# PADCFG_CTRL0_CFG0 register map
Vendor: Texas Instruments
Peripheral module from a debugger description file (folder am243x).
Registers are 32-bit, read-write, reset 0x214007 unless marked. A register's access mark holds for its fields unless they carry their own. Offsets are as the file gives them; lines under a group give offsets from that group; [hi:lo] are bit positions; {n}, {i} and the like mark numbered series; 'fields as' and 'values as' point back to an identical list; <NAME> marks a mode.

## PADCFG_CTRL0_CFG0
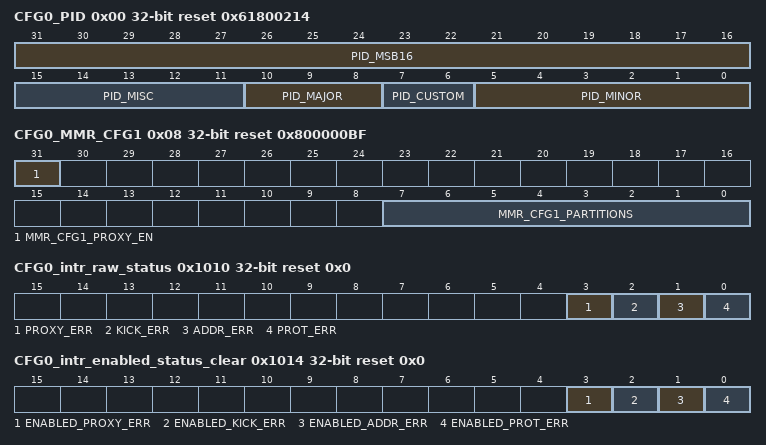
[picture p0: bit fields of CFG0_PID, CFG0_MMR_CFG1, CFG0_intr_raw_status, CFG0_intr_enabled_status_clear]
0x00 CFG0_PID ro reset 0x61800214
  [31:16] PID_MSB16, [15:11] PID_MISC, [10:8] PID_MAJOR, [7:6] PID_CUSTOM, [5:0] PID_MINOR
0x08 CFG0_MMR_CFG1 ro reset 0x800000BF
  [31] MMR_CFG1_PROXY_EN — Proxy addressing enabled
  [7:0] MMR_CFG1_PARTITIONS — Indicates present partitions
0x1008 CFG0_LOCK0_KICK0 reset 0x0
  [31:0] LOCK0_KICK0 — - KICK0 component
0x100C CFG0_LOCK0_KICK1 reset 0x0
  [31:0] LOCK0_KICK1 — - KICK1 component
0x1010 CFG0_intr_raw_status access not given reset 0x0
  [3] PROXY_ERR — Proxy0 access violation error. Raw status is read. Write a 1 to set the status. Writing a 0 has no effect. (access R/W1TS)
  [2] KICK_ERR — Kick access violation error. Raw status is read. Write a 1 to set the status. Writing a 0 has no effect. (access R/W1TS)
  [1] ADDR_ERR — Addressing violation error. Raw status is read. Write a 1 to set the status. Writing a 0 has no effect. (access R/W1TS)
  [0] PROT_ERR — Protection violation error. Raw status is read. Write a 1 to set the status. Writing a 0 has no effect. (access R/W1TS)
0x1014 CFG0_intr_enabled_status_clear access not given reset 0x0
  [3] ENABLED_PROXY_ERR — Proxy0 access violation error. Enabled status is read. Write a 1 to clear the status. Writing a 0 has no effect. (access R/W1TC)
  [2] ENABLED_KICK_ERR — Kick access violation error. Enabled status is read. Write a 1 to clear the status. Writing a 0 has no effect. (access R/W1TC)
  [1] ENABLED_ADDR_ERR — Addressing violation error. Enabled status is read. Write a 1 to clear the status. Writing a 0 has no effect. (access R/W1TC)
  [0] ENABLED_PROT_ERR — Protection violation error. Enabled status is read. Write a 1 to clear the status. Writing a 0 has no effect. (access R/W1TC)
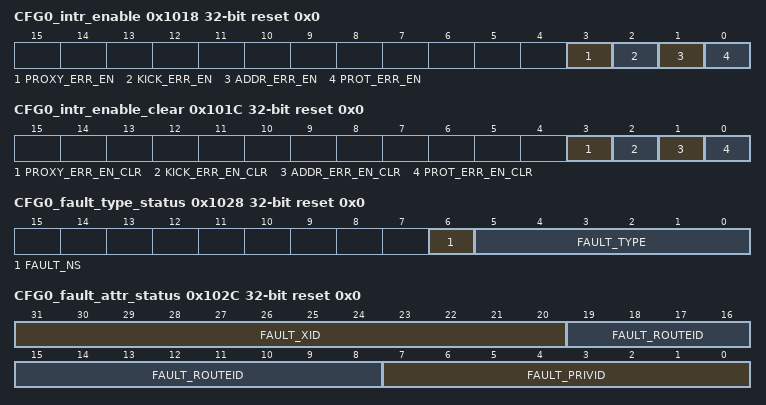
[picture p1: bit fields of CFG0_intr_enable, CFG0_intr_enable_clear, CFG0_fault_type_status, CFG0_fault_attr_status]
0x1018 CFG0_intr_enable access not given reset 0x0
  [3] PROXY_ERR_EN — Proxy0 access violation error enable. Write a 1 to set the enable. Writing a 0 has no effect. (access R/W1TS)
  [2] KICK_ERR_EN — Kick access violation error enable. Write a 1 to set the enable. Writing a 0 has no effect. (access R/W1TS)
  [1] ADDR_ERR_EN — Addressing violation error enable. Write a 1 to set the enable. Writing a 0 has no effect. (access R/W1TS)
  [0] PROT_ERR_EN — Protection violation error enable. Write a 1 to set the enable. Writing a 0 has no effect. (access R/W1TS)
0x101C CFG0_intr_enable_clear access not given reset 0x0
  [3] PROXY_ERR_EN_CLR — Proxy0 access violation error enable clear. Write a 1 to clear the enable. Writing a 0 has no effect. (access R/W1TC)
  [2] KICK_ERR_EN_CLR — Kick access violation error enable clear. Write a 1 to clear the enable. Writing a 0 has no effect. (access R/W1TC)
  [1] ADDR_ERR_EN_CLR — Addressing violation error enable clear. Write a 1 to clear the enable. Writing a 0 has no effect. (access R/W1TC)
  [0] PROT_ERR_EN_CLR — Protection violation error enable clear. Write a 1 to clear the enable. Writing a 0 has no effect. (access R/W1TC)
0x1020 CFG0_eoi reset 0x0
  [7:0] EOI_VECTOR — EOI vector value. Write this with interrupt distribution value in the chip.
0x1024 CFG0_fault_address ro reset 0x0
  [31:0] FAULT_ADDR — Fault Address.
0x1028 CFG0_fault_type_status ro reset 0x0
  [6] FAULT_NS — Non-secure access.
  [5:0] FAULT_TYPE — Fault Type 10_0000 = Supervisor read fault - priv = 1 dir = 1 dtype != 1 01_0000 = Supervisor write fault - priv = 1 dir = 0 00_1000 = Supervisor execute fault - priv = 1 dir = 1 dtype = 1 00_0100 = User read fault - priv = 0 dir = 1 dtype = 1 00_0010 = User write fault - priv = 0 dir = 0 00_0001 = User execute fault - priv = 0 dir = 1 dtype = 1 00_0000 = No fault
0x102C CFG0_fault_attr_status ro reset 0x0
  [31:20] FAULT_XID — XID.
  [19:8] FAULT_ROUTEID — Route ID.
  [7:0] FAULT_PRIVID — Privilege ID.
0x1030 CFG0_fault_clear wo reset 0x0
  [0] FAULT_CLR — Fault clear. Writing a 1 clears the current fault. Writing a 0 has no effect.
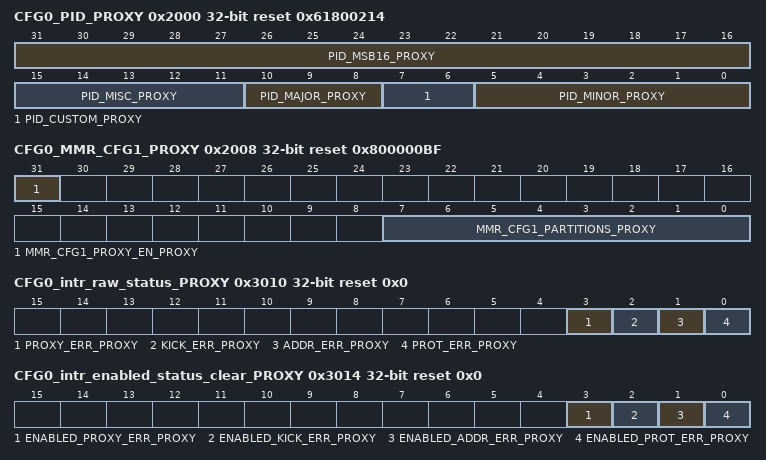
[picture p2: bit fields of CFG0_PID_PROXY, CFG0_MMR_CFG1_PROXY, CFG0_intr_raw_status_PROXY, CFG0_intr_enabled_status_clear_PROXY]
0x2000 CFG0_PID_PROXY ro reset 0x61800214
  [31:16] PID_MSB16_PROXY, [15:11] PID_MISC_PROXY, [10:8] PID_MAJOR_PROXY, [7:6] PID_CUSTOM_PROXY, [5:0] PID_MINOR_PROXY
0x2008 CFG0_MMR_CFG1_PROXY ro reset 0x800000BF
  [31] MMR_CFG1_PROXY_EN_PROXY — Proxy addressing enabled
  [7:0] MMR_CFG1_PARTITIONS_PROXY — Indicates present partitions
0x3008 CFG0_LOCK0_KICK0_PROXY reset 0x0
  [31:0] LOCK0_KICK0_PROXY — - KICK0 component
0x300C CFG0_LOCK0_KICK1_PROXY reset 0x0
  [31:0] LOCK0_KICK1_PROXY — - KICK1 component
0x3010 CFG0_intr_raw_status_PROXY access not given reset 0x0
  [3] PROXY_ERR_PROXY — Proxy0 access violation error. Raw status is read. Write a 1 to set the status. Writing a 0 has no effect. (access R/W1TS)
  [2] KICK_ERR_PROXY — Kick access violation error. Raw status is read. Write a 1 to set the status. Writing a 0 has no effect. (access R/W1TS)
  [1] ADDR_ERR_PROXY — Addressing violation error. Raw status is read. Write a 1 to set the status. Writing a 0 has no effect. (access R/W1TS)
  [0] PROT_ERR_PROXY — Protection violation error. Raw status is read. Write a 1 to set the status. Writing a 0 has no effect. (access R/W1TS)
0x3014 CFG0_intr_enabled_status_clear_PROXY access not given reset 0x0
  [3] ENABLED_PROXY_ERR_PROXY — Proxy0 access violation error. Enabled status is read. Write a 1 to clear the status. Writing a 0 has no effect. (access R/W1TC)
  [2] ENABLED_KICK_ERR_PROXY — Kick access violation error. Enabled status is read. Write a 1 to clear the status. Writing a 0 has no effect. (access R/W1TC)
  [1] ENABLED_ADDR_ERR_PROXY — Addressing violation error. Enabled status is read. Write a 1 to clear the status. Writing a 0 has no effect. (access R/W1TC)
  [0] ENABLED_PROT_ERR_PROXY — Protection violation error. Enabled status is read. Write a 1 to clear the status. Writing a 0 has no effect. (access R/W1TC)
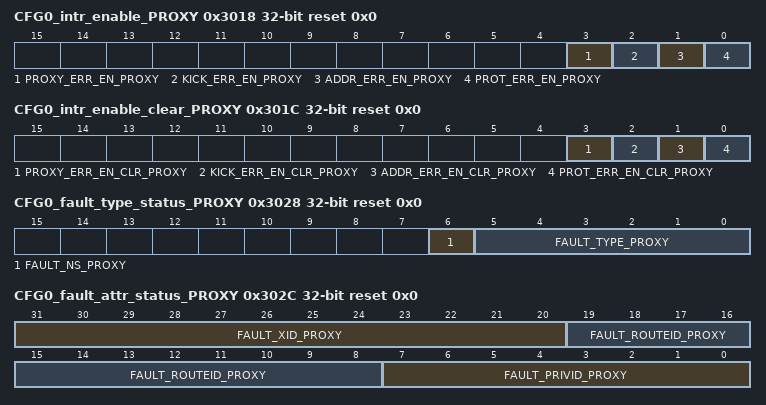
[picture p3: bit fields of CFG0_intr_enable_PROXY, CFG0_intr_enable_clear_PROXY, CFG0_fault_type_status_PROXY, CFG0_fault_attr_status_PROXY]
0x3018 CFG0_intr_enable_PROXY access not given reset 0x0
  [3] PROXY_ERR_EN_PROXY — Proxy0 access violation error enable. Write a 1 to set the enable. Writing a 0 has no effect. (access R/W1TS)
  [2] KICK_ERR_EN_PROXY — Kick access violation error enable. Write a 1 to set the enable. Writing a 0 has no effect. (access R/W1TS)
  [1] ADDR_ERR_EN_PROXY — Addressing violation error enable. Write a 1 to set the enable. Writing a 0 has no effect. (access R/W1TS)
  [0] PROT_ERR_EN_PROXY — Protection violation error enable. Write a 1 to set the enable. Writing a 0 has no effect. (access R/W1TS)
0x301C CFG0_intr_enable_clear_PROXY access not given reset 0x0
  [3] PROXY_ERR_EN_CLR_PROXY — Proxy0 access violation error enable clear. Write a 1 to clear the enable. Writing a 0 has no effect. (access R/W1TC)
  [2] KICK_ERR_EN_CLR_PROXY — Kick access violation error enable clear. Write a 1 to clear the enable. Writing a 0 has no effect. (access R/W1TC)
  [1] ADDR_ERR_EN_CLR_PROXY — Addressing violation error enable clear. Write a 1 to clear the enable. Writing a 0 has no effect. (access R/W1TC)
  [0] PROT_ERR_EN_CLR_PROXY — Protection violation error enable clear. Write a 1 to clear the enable. Writing a 0 has no effect. (access R/W1TC)
0x3020 CFG0_eoi_PROXY reset 0x0
  [7:0] EOI_VECTOR_PROXY — EOI vector value. Write this with interrupt distribution value in the chip.
0x3024 CFG0_fault_address_PROXY ro reset 0x0
  [31:0] FAULT_ADDR_PROXY — Fault Address.
0x3028 CFG0_fault_type_status_PROXY ro reset 0x0
  [6] FAULT_NS_PROXY — Non-secure access.
  [5:0] FAULT_TYPE_PROXY — Fault Type 10_0000 = Supervisor read fault - priv = 1 dir = 1 dtype != 1 01_0000 = Supervisor write fault - priv = 1 dir = 0 00_1000 = Supervisor execute fault - priv = 1 dir = 1 dtype = 1 00_0100 = User read fault - priv = 0 dir = 1 dtype = 1 00_0010 = User write fault - priv = 0 dir = 0 00_0001 = User execute fault - priv = 0 dir = 1 dtype = 1 00_0000 = No fault
0x302C CFG0_fault_attr_status_PROXY ro reset 0x0
  [31:20] FAULT_XID_PROXY — XID.
  [19:8] FAULT_ROUTEID_PROXY — Route ID.
  [7:0] FAULT_PRIVID_PROXY — Privilege ID.
0x3030 CFG0_fault_clear_PROXY wo reset 0x0
  [0] FAULT_CLR_PROXY — Fault clear. Writing a 1 clears the current fault. Writing a 0 has no effect.
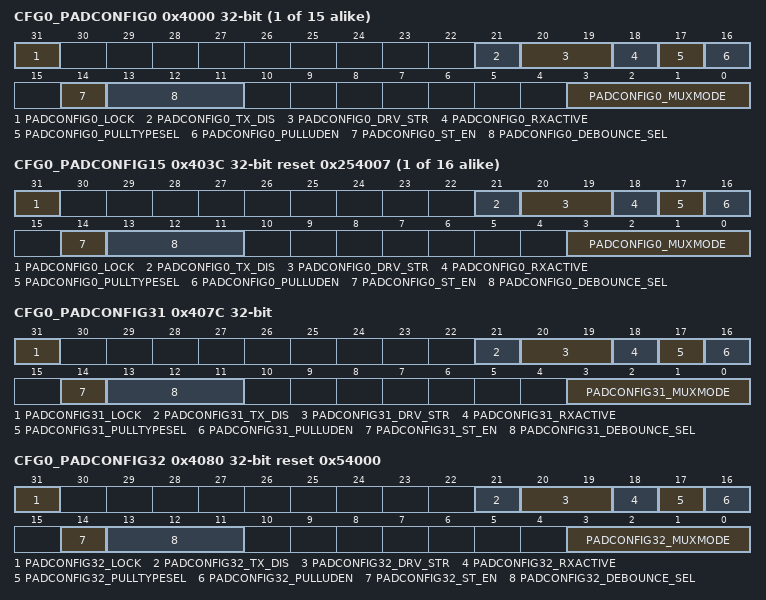
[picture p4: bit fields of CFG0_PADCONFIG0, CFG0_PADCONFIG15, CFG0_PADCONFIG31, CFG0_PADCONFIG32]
{0x4000+4i} CFG0_PADCONFIG{i} (i=0..14)
  [31] PADCONFIG{i}_LOCK — Lock 0 - Padconfig register is unlocked 1 - Padconfig register is locked from further writes
  [21] PADCONFIG{i}_TX_DIS — Driver Disable 0 - Driver is enabled 1 - Driver is disabled
  [20:19] PADCONFIG{i}_DRV_STR — Drive Strength Control . Selects the drive strength value for LVCMOS pins. (Does not apply to other pin types)
  [18] PADCONFIG{i}_RXACTIVE — Input enable for the Pad 0 - Receiver disabled 1 - Receiver enabled
  [17] PADCONFIG{i}_PULLTYPESEL — Pad Pullup / Pulldown type selection 0 - Pulldown selected 1 - Pullup selected
  [16] PADCONFIG{i}_PULLUDEN — Pad Pullup / Pulldown enable. This is an active low signal. 0 - Pullup / Pulldown enabled 1 - Pullup / Pulldown disabled
  [14] PADCONFIG{i}_ST_EN — Receiver Schmitt Trigger enable 0 - Schmitt trigger input disabled 1 - Schmitt trigger input enabled
  [13:11] PADCONFIG{i}_DEBOUNCE_SEL — Selects the debouce period for the pad.
  [3:0] PADCONFIG{i}_MUXMODE — Pad functional signal mux selection Field values (others are reserved): 4'b0000 - Mux Mode 0 4'b0001 - Mux Mode 1 4'b0010 - Mux Mode 2 4'b0011 - Mux Mode 3 4'b0100 - Mux Mode 4 4'b0101 - Mux Mode 5 4'b0110 - Mux Mode 6 4'b0111 - Mux Mode 7 4'b1000 - Mux Mode 8 4'b1001 - Mux Mode 9 4'b1010 - Mux Mode 10 4'b1011 - Mux Mode 11 4'b1100 - Mux Mode 12 4'b1101 - Mux Mode 13 4'b1110 - Mux Mode 14 4'b1111 - Mux Mode 15
{0x4000+4i} CFG0_PADCONFIG{i} reset 0x254007 (i=15..30)
  fields as CFG0_PADCONFIG0
0x407C CFG0_PADCONFIG31
  [31] PADCONFIG31_LOCK — Lock 0 - Padconfig register is unlocked 1 - Padconfig register is locked from further writes
  [21] PADCONFIG31_TX_DIS — Driver Disable 0 - Driver is enabled 1 - Driver is disabled
  [20:19] PADCONFIG31_DRV_STR — Drive Strength Control . Selects the drive strength value for LVCMOS pins. (Does not apply to other pin types)
  [18] PADCONFIG31_RXACTIVE — Input enable for the Pad 0 - Receiver disabled 1 - Receiver enabled
  [17] PADCONFIG31_PULLTYPESEL — Pad Pullup / Pulldown type selection 0 - Pulldown selected 1 - Pullup selected
  [16] PADCONFIG31_PULLUDEN — Pad Pullup / Pulldown enable. This is an active low signal. 0 - Pullup / Pulldown enabled 1 - Pullup / Pulldown disabled
  [14] PADCONFIG31_ST_EN — Receiver Schmitt Trigger enable 0 - Schmitt trigger input disabled 1 - Schmitt trigger input enabled
  [13:11] PADCONFIG31_DEBOUNCE_SEL — Selects the debouce period for the pad.
  [3:0] PADCONFIG31_MUXMODE — Pad functional signal mux selection Field values (others are reserved): 4'b0000 - Mux Mode 0 4'b0001 - Mux Mode 1 4'b0010 - Mux Mode 2 4'b0011 - Mux Mode 3 4'b0100 - Mux Mode 4 4'b0101 - Mux Mode 5 4'b0110 - Mux Mode 6 4'b0111 - Mux Mode 7 4'b1000 - Mux Mode 8 4'b1001 - Mux Mode 9 4'b1010 - Mux Mode 10 4'b1011 - Mux Mode 11 4'b1100 - Mux Mode 12 4'b1101 - Mux Mode 13 4'b1110 - Mux Mode 14 4'b1111 - Mux Mode 15
0x4080 CFG0_PADCONFIG32 reset 0x54000
  [31] PADCONFIG32_LOCK — Lock 0 - Padconfig register is unlocked 1 - Padconfig register is locked from further writes
  [21] PADCONFIG32_TX_DIS — Driver Disable 0 - Driver is enabled 1 - Driver is disabled
  [20:19] PADCONFIG32_DRV_STR — Drive Strength Control . Selects the drive strength value for LVCMOS pins. (Does not apply to other pin types)
  [18] PADCONFIG32_RXACTIVE — Input enable for the Pad 0 - Receiver disabled 1 - Receiver enabled
  [17] PADCONFIG32_PULLTYPESEL — Pad Pullup / Pulldown type selection 0 - Pulldown selected 1 - Pullup selected
  [16] PADCONFIG32_PULLUDEN — Pad Pullup / Pulldown enable. This is an active low signal. 0 - Pullup / Pulldown enabled 1 - Pullup / Pulldown disabled
  [14] PADCONFIG32_ST_EN — Receiver Schmitt Trigger enable 0 - Schmitt trigger input disabled 1 - Schmitt trigger input enabled
  [13:11] PADCONFIG32_DEBOUNCE_SEL — Selects the debouce period for the pad.
  [3:0] PADCONFIG32_MUXMODE — Pad functional signal mux selection Field values (others are reserved): 4'b0000 - Mux Mode 0 4'b0001 - Mux Mode 1 4'b0010 - Mux Mode 2 4'b0011 - Mux Mode 3 4'b0100 - Mux Mode 4 4'b0101 - Mux Mode 5 4'b0110 - Mux Mode 6 4'b0111 - Mux Mode 7 4'b1000 - Mux Mode 8 4'b1001 - Mux Mode 9 4'b1010 - Mux Mode 10 4'b1011 - Mux Mode 11 4'b1100 - Mux Mode 12 4'b1101 - Mux Mode 13 4'b1110 - Mux Mode 14 4'b1111 - Mux Mode 15
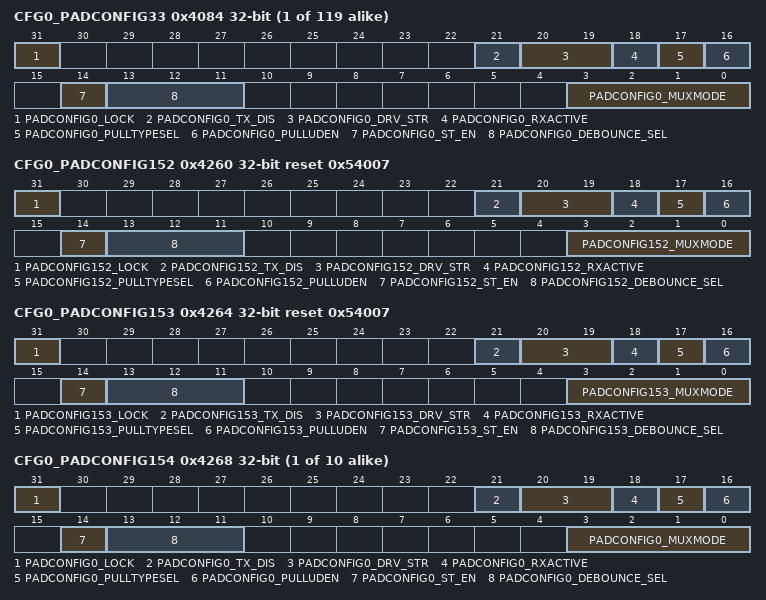
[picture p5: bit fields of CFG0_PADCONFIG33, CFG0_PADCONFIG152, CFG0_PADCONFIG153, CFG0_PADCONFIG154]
{0x4000+4i} CFG0_PADCONFIG{i} (i=33..151)
  fields as CFG0_PADCONFIG0
0x4260 CFG0_PADCONFIG152 reset 0x54007
  [31] PADCONFIG152_LOCK — Lock 0 - Padconfig register is unlocked 1 - Padconfig register is locked from further writes
  [21] PADCONFIG152_TX_DIS — Driver Disable 0 - Driver is enabled 1 - Driver is disabled
  [20:19] PADCONFIG152_DRV_STR — Drive Strength Control . Selects the drive strength value for LVCMOS pins. (Does not apply to other pin types)
  [18] PADCONFIG152_RXACTIVE — Input enable for the Pad 0 - Receiver disabled 1 - Receiver enabled
  [17] PADCONFIG152_PULLTYPESEL — Pad Pullup / Pulldown type selection 0 - Pulldown selected 1 - Pullup selected
  [16] PADCONFIG152_PULLUDEN — Pad Pullup / Pulldown enable. This is an active low signal. 0 - Pullup / Pulldown enabled 1 - Pullup / Pulldown disabled
  [14] PADCONFIG152_ST_EN — Receiver Schmitt Trigger enable 0 - Schmitt trigger input disabled 1 - Schmitt trigger input enabled
  [13:11] PADCONFIG152_DEBOUNCE_SEL — Selects the debouce period for the pad.
  [3:0] PADCONFIG152_MUXMODE — Pad functional signal mux selection Field values (others are reserved): 4'b0000 - Mux Mode 0 4'b0001 - Mux Mode 1 4'b0010 - Mux Mode 2 4'b0011 - Mux Mode 3 4'b0100 - Mux Mode 4 4'b0101 - Mux Mode 5 4'b0110 - Mux Mode 6 4'b0111 - Mux Mode 7 4'b1000 - Mux Mode 8 4'b1001 - Mux Mode 9 4'b1010 - Mux Mode 10 4'b1011 - Mux Mode 11 4'b1100 - Mux Mode 12 4'b1101 - Mux Mode 13 4'b1110 - Mux Mode 14 4'b1111 - Mux Mode 15
0x4264 CFG0_PADCONFIG153 reset 0x54007
  [31] PADCONFIG153_LOCK — Lock 0 - Padconfig register is unlocked 1 - Padconfig register is locked from further writes
  [21] PADCONFIG153_TX_DIS — Driver Disable 0 - Driver is enabled 1 - Driver is disabled
  [20:19] PADCONFIG153_DRV_STR — Drive Strength Control . Selects the drive strength value for LVCMOS pins. (Does not apply to other pin types)
  [18] PADCONFIG153_RXACTIVE — Input enable for the Pad 0 - Receiver disabled 1 - Receiver enabled
  [17] PADCONFIG153_PULLTYPESEL — Pad Pullup / Pulldown type selection 0 - Pulldown selected 1 - Pullup selected
  [16] PADCONFIG153_PULLUDEN — Pad Pullup / Pulldown enable. This is an active low signal. 0 - Pullup / Pulldown enabled 1 - Pullup / Pulldown disabled
  [14] PADCONFIG153_ST_EN — Receiver Schmitt Trigger enable 0 - Schmitt trigger input disabled 1 - Schmitt trigger input enabled
  [13:11] PADCONFIG153_DEBOUNCE_SEL — Selects the debouce period for the pad.
  [3:0] PADCONFIG153_MUXMODE — Pad functional signal mux selection Field values (others are reserved): 4'b0000 - Mux Mode 0 4'b0001 - Mux Mode 1 4'b0010 - Mux Mode 2 4'b0011 - Mux Mode 3 4'b0100 - Mux Mode 4 4'b0101 - Mux Mode 5 4'b0110 - Mux Mode 6 4'b0111 - Mux Mode 7 4'b1000 - Mux Mode 8 4'b1001 - Mux Mode 9 4'b1010 - Mux Mode 10 4'b1011 - Mux Mode 11 4'b1100 - Mux Mode 12 4'b1101 - Mux Mode 13 4'b1110 - Mux Mode 14 4'b1111 - Mux Mode 15
{0x4000+4i} CFG0_PADCONFIG{i} (i=154..163)
  fields as CFG0_PADCONFIG0
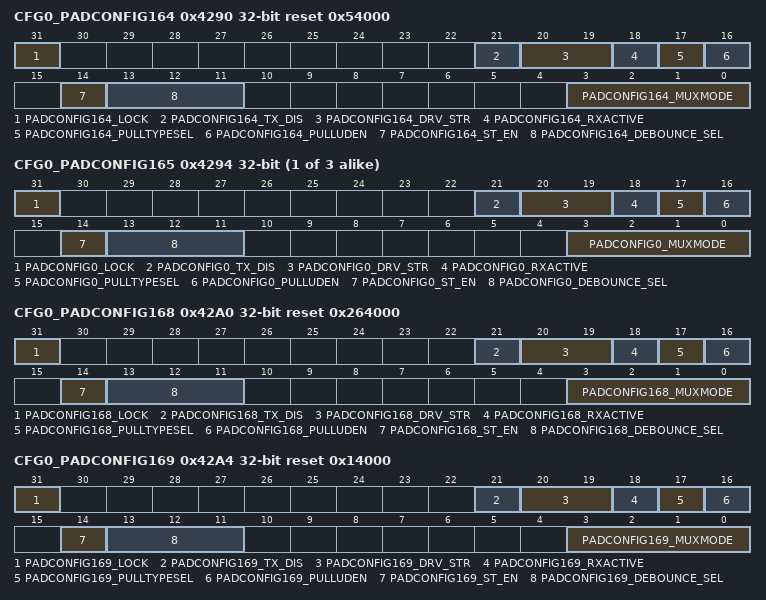
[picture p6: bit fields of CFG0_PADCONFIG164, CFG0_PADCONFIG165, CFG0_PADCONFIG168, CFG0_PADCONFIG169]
0x4290 CFG0_PADCONFIG164 reset 0x54000
  [31] PADCONFIG164_LOCK — Lock 0 - Padconfig register is unlocked 1 - Padconfig register is locked from further writes
  [21] PADCONFIG164_TX_DIS — Driver Disable 0 - Driver is enabled 1 - Driver is disabled
  [20:19] PADCONFIG164_DRV_STR — Drive Strength Control . Selects the drive strength value for LVCMOS pins. (Does not apply to other pin types)
  [18] PADCONFIG164_RXACTIVE — Input enable for the Pad 0 - Receiver disabled 1 - Receiver enabled
  [17] PADCONFIG164_PULLTYPESEL — Pad Pullup / Pulldown type selection 0 - Pulldown selected 1 - Pullup selected
  [16] PADCONFIG164_PULLUDEN — Pad Pullup / Pulldown enable. This is an active low signal. 0 - Pullup / Pulldown enabled 1 - Pullup / Pulldown disabled
  [14] PADCONFIG164_ST_EN — Receiver Schmitt Trigger enable 0 - Schmitt trigger input disabled 1 - Schmitt trigger input enabled
  [13:11] PADCONFIG164_DEBOUNCE_SEL — Selects the debouce period for the pad.
  [3:0] PADCONFIG164_MUXMODE — Pad functional signal mux selection Field values (others are reserved): 4'b0000 - Mux Mode 0 4'b0001 - Mux Mode 1 4'b0010 - Mux Mode 2 4'b0011 - Mux Mode 3 4'b0100 - Mux Mode 4 4'b0101 - Mux Mode 5 4'b0110 - Mux Mode 6 4'b0111 - Mux Mode 7 4'b1000 - Mux Mode 8 4'b1001 - Mux Mode 9 4'b1010 - Mux Mode 10 4'b1011 - Mux Mode 11 4'b1100 - Mux Mode 12 4'b1101 - Mux Mode 13 4'b1110 - Mux Mode 14 4'b1111 - Mux Mode 15
{0x4000+4i} CFG0_PADCONFIG{i} (i=165..167)
  fields as CFG0_PADCONFIG0
0x42A0 CFG0_PADCONFIG168 reset 0x264000
  [31] PADCONFIG168_LOCK — Lock 0 - Padconfig register is unlocked 1 - Padconfig register is locked from further writes
  [21] PADCONFIG168_TX_DIS — Driver Disable 0 - Driver is enabled 1 - Driver is disabled
  [20:19] PADCONFIG168_DRV_STR — Drive Strength Control . Selects the drive strength value for LVCMOS pins. (Does not apply to other pin types)
  [18] PADCONFIG168_RXACTIVE — Input enable for the Pad 0 - Receiver disabled 1 - Receiver enabled
  [17] PADCONFIG168_PULLTYPESEL — Pad Pullup / Pulldown type selection 0 - Pulldown selected 1 - Pullup selected
  [16] PADCONFIG168_PULLUDEN — Pad Pullup / Pulldown enable. This is an active low signal. 0 - Pullup / Pulldown enabled 1 - Pullup / Pulldown disabled
  [14] PADCONFIG168_ST_EN — Receiver Schmitt Trigger enable 0 - Schmitt trigger input disabled 1 - Schmitt trigger input enabled
  [13:11] PADCONFIG168_DEBOUNCE_SEL — Selects the debouce period for the pad.
  [3:0] PADCONFIG168_MUXMODE — Pad functional signal mux selection Field values (others are reserved): 4'b0000 - Mux Mode 0 4'b0001 - Mux Mode 1 4'b0010 - Mux Mode 2 4'b0011 - Mux Mode 3 4'b0100 - Mux Mode 4 4'b0101 - Mux Mode 5 4'b0110 - Mux Mode 6 4'b0111 - Mux Mode 7 4'b1000 - Mux Mode 8 4'b1001 - Mux Mode 9 4'b1010 - Mux Mode 10 4'b1011 - Mux Mode 11 4'b1100 - Mux Mode 12 4'b1101 - Mux Mode 13 4'b1110 - Mux Mode 14 4'b1111 - Mux Mode 15
0x42A4 CFG0_PADCONFIG169 reset 0x14000
  [31] PADCONFIG169_LOCK — Lock 0 - Padconfig register is unlocked 1 - Padconfig register is locked from further writes
  [21] PADCONFIG169_TX_DIS — Driver Disable 0 - Driver is enabled 1 - Driver is disabled
  [20:19] PADCONFIG169_DRV_STR — Drive Strength Control . Selects the drive strength value for LVCMOS pins. (Does not apply to other pin types)
  [18] PADCONFIG169_RXACTIVE — Input enable for the Pad 0 - Receiver disabled 1 - Receiver enabled
  [17] PADCONFIG169_PULLTYPESEL — Pad Pullup / Pulldown type selection 0 - Pulldown selected 1 - Pullup selected
  [16] PADCONFIG169_PULLUDEN — Pad Pullup / Pulldown enable. This is an active low signal. 0 - Pullup / Pulldown enabled 1 - Pullup / Pulldown disabled
  [14] PADCONFIG169_ST_EN — Receiver Schmitt Trigger enable 0 - Schmitt trigger input disabled 1 - Schmitt trigger input enabled
  [13:11] PADCONFIG169_DEBOUNCE_SEL — Selects the debouce period for the pad.
  [3:0] PADCONFIG169_MUXMODE — Pad functional signal mux selection Field values (others are reserved): 4'b0000 - Mux Mode 0 4'b0001 - Mux Mode 1 4'b0010 - Mux Mode 2 4'b0011 - Mux Mode 3 4'b0100 - Mux Mode 4 4'b0101 - Mux Mode 5 4'b0110 - Mux Mode 6 4'b0111 - Mux Mode 7 4'b1000 - Mux Mode 8 4'b1001 - Mux Mode 9 4'b1010 - Mux Mode 10 4'b1011 - Mux Mode 11 4'b1100 - Mux Mode 12 4'b1101 - Mux Mode 13 4'b1110 - Mux Mode 14 4'b1111 - Mux Mode 15
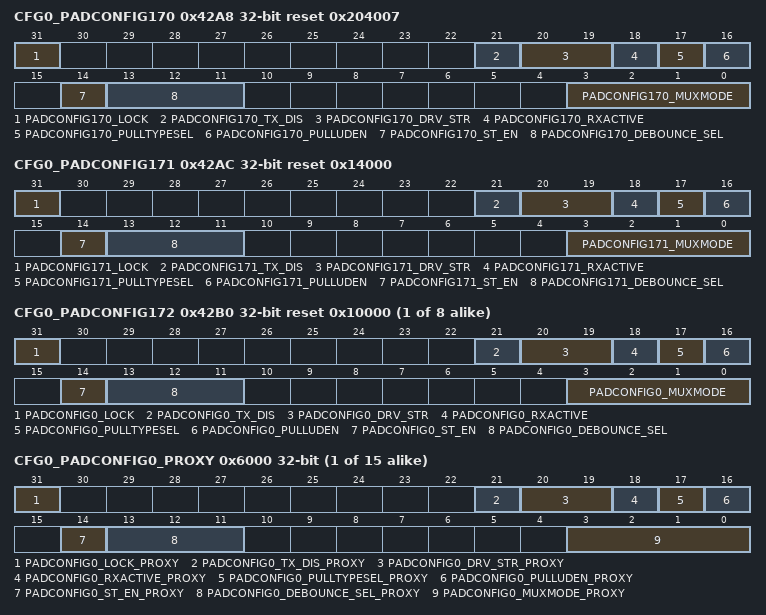
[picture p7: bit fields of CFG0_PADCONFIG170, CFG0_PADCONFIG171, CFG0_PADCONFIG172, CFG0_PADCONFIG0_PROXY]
0x42A8 CFG0_PADCONFIG170 reset 0x204007
  [31] PADCONFIG170_LOCK — Lock 0 - Padconfig register is unlocked 1 - Padconfig register is locked from further writes
  [21] PADCONFIG170_TX_DIS — Driver Disable 0 - Driver is enabled 1 - Driver is disabled
  [20:19] PADCONFIG170_DRV_STR — Drive Strength Control . Selects the drive strength value for LVCMOS pins. (Does not apply to other pin types)
  [18] PADCONFIG170_RXACTIVE — Input enable for the Pad 0 - Receiver disabled 1 - Receiver enabled
  [17] PADCONFIG170_PULLTYPESEL — Pad Pullup / Pulldown type selection 0 - Pulldown selected 1 - Pullup selected
  [16] PADCONFIG170_PULLUDEN — Pad Pullup / Pulldown enable. This is an active low signal. 0 - Pullup / Pulldown enabled 1 - Pullup / Pulldown disabled
  [14] PADCONFIG170_ST_EN — Receiver Schmitt Trigger enable 0 - Schmitt trigger input disabled 1 - Schmitt trigger input enabled
  [13:11] PADCONFIG170_DEBOUNCE_SEL — Selects the debouce period for the pad.
  [3:0] PADCONFIG170_MUXMODE — Pad functional signal mux selection Field values (others are reserved): 4'b0000 - Mux Mode 0 4'b0001 - Mux Mode 1 4'b0010 - Mux Mode 2 4'b0011 - Mux Mode 3 4'b0100 - Mux Mode 4 4'b0101 - Mux Mode 5 4'b0110 - Mux Mode 6 4'b0111 - Mux Mode 7 4'b1000 - Mux Mode 8 4'b1001 - Mux Mode 9 4'b1010 - Mux Mode 10 4'b1011 - Mux Mode 11 4'b1100 - Mux Mode 12 4'b1101 - Mux Mode 13 4'b1110 - Mux Mode 14 4'b1111 - Mux Mode 15
0x42AC CFG0_PADCONFIG171 reset 0x14000
  [31] PADCONFIG171_LOCK — Lock 0 - Padconfig register is unlocked 1 - Padconfig register is locked from further writes
  [21] PADCONFIG171_TX_DIS — Driver Disable 0 - Driver is enabled 1 - Driver is disabled
  [20:19] PADCONFIG171_DRV_STR — Drive Strength Control . Selects the drive strength value for LVCMOS pins. (Does not apply to other pin types)
  [18] PADCONFIG171_RXACTIVE — Input enable for the Pad 0 - Receiver disabled 1 - Receiver enabled
  [17] PADCONFIG171_PULLTYPESEL — Pad Pullup / Pulldown type selection 0 - Pulldown selected 1 - Pullup selected
  [16] PADCONFIG171_PULLUDEN — Pad Pullup / Pulldown enable. This is an active low signal. 0 - Pullup / Pulldown enabled 1 - Pullup / Pulldown disabled
  [14] PADCONFIG171_ST_EN — Receiver Schmitt Trigger enable 0 - Schmitt trigger input disabled 1 - Schmitt trigger input enabled
  [13:11] PADCONFIG171_DEBOUNCE_SEL — Selects the debouce period for the pad.
  [3:0] PADCONFIG171_MUXMODE — Pad functional signal mux selection Field values (others are reserved): 4'b0000 - Mux Mode 0 4'b0001 - Mux Mode 1 4'b0010 - Mux Mode 2 4'b0011 - Mux Mode 3 4'b0100 - Mux Mode 4 4'b0101 - Mux Mode 5 4'b0110 - Mux Mode 6 4'b0111 - Mux Mode 7 4'b1000 - Mux Mode 8 4'b1001 - Mux Mode 9 4'b1010 - Mux Mode 10 4'b1011 - Mux Mode 11 4'b1100 - Mux Mode 12 4'b1101 - Mux Mode 13 4'b1110 - Mux Mode 14 4'b1111 - Mux Mode 15
{0x4000+4i} CFG0_PADCONFIG{i} reset 0x10000 (i=172..179)
  fields as CFG0_PADCONFIG0
0x5008 CFG0_LOCK1_KICK0 reset 0x0
  [31:0] LOCK1_KICK0 — - KICK0 component
0x500C CFG0_LOCK1_KICK1 reset 0x0
  [31:0] LOCK1_KICK1 — - KICK1 component
{0x6000+4i} CFG0_PADCONFIG{i}_PROXY (i=0..14)
  [31] PADCONFIG{i}_LOCK_PROXY — Lock 0 - Padconfig register is unlocked 1 - Padconfig register is locked from further writes
  [21] PADCONFIG{i}_TX_DIS_PROXY — Driver Disable 0 - Driver is enabled 1 - Driver is disabled
  [20:19] PADCONFIG{i}_DRV_STR_PROXY — Drive Strength Control . Selects the drive strength value for LVCMOS pins. (Does not apply to other pin types)
  [18] PADCONFIG{i}_RXACTIVE_PROXY — Input enable for the Pad 0 - Receiver disabled 1 - Receiver enabled
  [17] PADCONFIG{i}_PULLTYPESEL_PROXY — Pad Pullup / Pulldown type selection 0 - Pulldown selected 1 - Pullup selected
  [16] PADCONFIG{i}_PULLUDEN_PROXY — Pad Pullup / Pulldown enable. This is an active low signal. 0 - Pullup / Pulldown enabled 1 - Pullup / Pulldown disabled
  [14] PADCONFIG{i}_ST_EN_PROXY — Receiver Schmitt Trigger enable 0 - Schmitt trigger input disabled 1 - Schmitt trigger input enabled
  [13:11] PADCONFIG{i}_DEBOUNCE_SEL_PROXY — Selects the debouce period for the pad.
  [3:0] PADCONFIG{i}_MUXMODE_PROXY — Pad functional signal mux selection Field values (others are reserved): 4'b0000 - Mux Mode 0 4'b0001 - Mux Mode 1 4'b0010 - Mux Mode 2 4'b0011 - Mux Mode 3 4'b0100 - Mux Mode 4 4'b0101 - Mux Mode 5 4'b0110 - Mux Mode 6 4'b0111 - Mux Mode 7 4'b1000 - Mux Mode 8 4'b1001 - Mux Mode 9 4'b1010 - Mux Mode 10 4'b1011 - Mux Mode 11 4'b1100 - Mux Mode 12 4'b1101 - Mux Mode 13 4'b1110 - Mux Mode 14 4'b1111 - Mux Mode 15
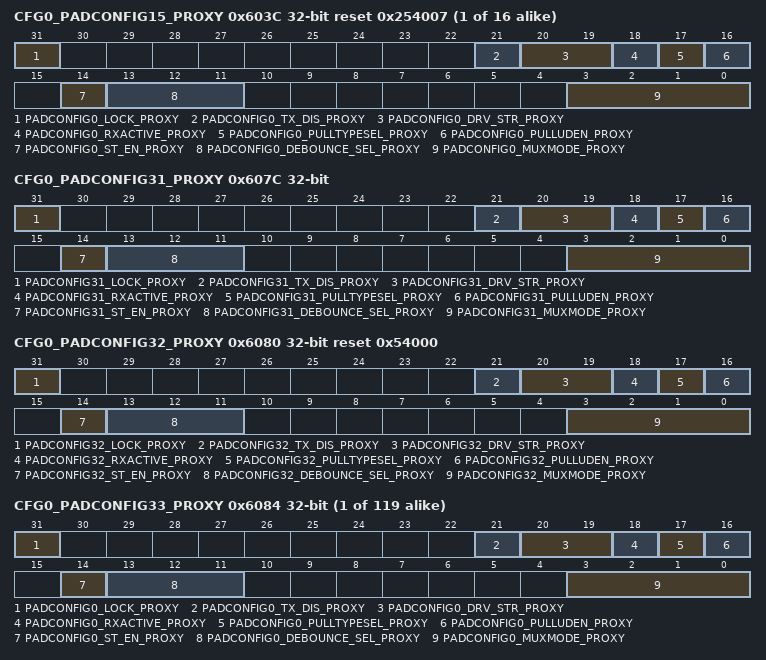
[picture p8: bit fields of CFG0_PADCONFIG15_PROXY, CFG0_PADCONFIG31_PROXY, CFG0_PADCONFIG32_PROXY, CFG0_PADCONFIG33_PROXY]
{0x6000+4i} CFG0_PADCONFIG{i}_PROXY reset 0x254007 (i=15..30)
  fields as CFG0_PADCONFIG0_PROXY
0x607C CFG0_PADCONFIG31_PROXY
  [31] PADCONFIG31_LOCK_PROXY — Lock 0 - Padconfig register is unlocked 1 - Padconfig register is locked from further writes
  [21] PADCONFIG31_TX_DIS_PROXY — Driver Disable 0 - Driver is enabled 1 - Driver is disabled
  [20:19] PADCONFIG31_DRV_STR_PROXY — Drive Strength Control . Selects the drive strength value for LVCMOS pins. (Does not apply to other pin types)
  [18] PADCONFIG31_RXACTIVE_PROXY — Input enable for the Pad 0 - Receiver disabled 1 - Receiver enabled
  [17] PADCONFIG31_PULLTYPESEL_PROXY — Pad Pullup / Pulldown type selection 0 - Pulldown selected 1 - Pullup selected
  [16] PADCONFIG31_PULLUDEN_PROXY — Pad Pullup / Pulldown enable. This is an active low signal. 0 - Pullup / Pulldown enabled 1 - Pullup / Pulldown disabled
  [14] PADCONFIG31_ST_EN_PROXY — Receiver Schmitt Trigger enable 0 - Schmitt trigger input disabled 1 - Schmitt trigger input enabled
  [13:11] PADCONFIG31_DEBOUNCE_SEL_PROXY — Selects the debouce period for the pad.
  [3:0] PADCONFIG31_MUXMODE_PROXY — Pad functional signal mux selection Field values (others are reserved): 4'b0000 - Mux Mode 0 4'b0001 - Mux Mode 1 4'b0010 - Mux Mode 2 4'b0011 - Mux Mode 3 4'b0100 - Mux Mode 4 4'b0101 - Mux Mode 5 4'b0110 - Mux Mode 6 4'b0111 - Mux Mode 7 4'b1000 - Mux Mode 8 4'b1001 - Mux Mode 9 4'b1010 - Mux Mode 10 4'b1011 - Mux Mode 11 4'b1100 - Mux Mode 12 4'b1101 - Mux Mode 13 4'b1110 - Mux Mode 14 4'b1111 - Mux Mode 15
0x6080 CFG0_PADCONFIG32_PROXY reset 0x54000
  [31] PADCONFIG32_LOCK_PROXY — Lock 0 - Padconfig register is unlocked 1 - Padconfig register is locked from further writes
  [21] PADCONFIG32_TX_DIS_PROXY — Driver Disable 0 - Driver is enabled 1 - Driver is disabled
  [20:19] PADCONFIG32_DRV_STR_PROXY — Drive Strength Control . Selects the drive strength value for LVCMOS pins. (Does not apply to other pin types)
  [18] PADCONFIG32_RXACTIVE_PROXY — Input enable for the Pad 0 - Receiver disabled 1 - Receiver enabled
  [17] PADCONFIG32_PULLTYPESEL_PROXY — Pad Pullup / Pulldown type selection 0 - Pulldown selected 1 - Pullup selected
  [16] PADCONFIG32_PULLUDEN_PROXY — Pad Pullup / Pulldown enable. This is an active low signal. 0 - Pullup / Pulldown enabled 1 - Pullup / Pulldown disabled
  [14] PADCONFIG32_ST_EN_PROXY — Receiver Schmitt Trigger enable 0 - Schmitt trigger input disabled 1 - Schmitt trigger input enabled
  [13:11] PADCONFIG32_DEBOUNCE_SEL_PROXY — Selects the debouce period for the pad.
  [3:0] PADCONFIG32_MUXMODE_PROXY — Pad functional signal mux selection Field values (others are reserved): 4'b0000 - Mux Mode 0 4'b0001 - Mux Mode 1 4'b0010 - Mux Mode 2 4'b0011 - Mux Mode 3 4'b0100 - Mux Mode 4 4'b0101 - Mux Mode 5 4'b0110 - Mux Mode 6 4'b0111 - Mux Mode 7 4'b1000 - Mux Mode 8 4'b1001 - Mux Mode 9 4'b1010 - Mux Mode 10 4'b1011 - Mux Mode 11 4'b1100 - Mux Mode 12 4'b1101 - Mux Mode 13 4'b1110 - Mux Mode 14 4'b1111 - Mux Mode 15
{0x6000+4i} CFG0_PADCONFIG{i}_PROXY (i=33..151)
  fields as CFG0_PADCONFIG0_PROXY
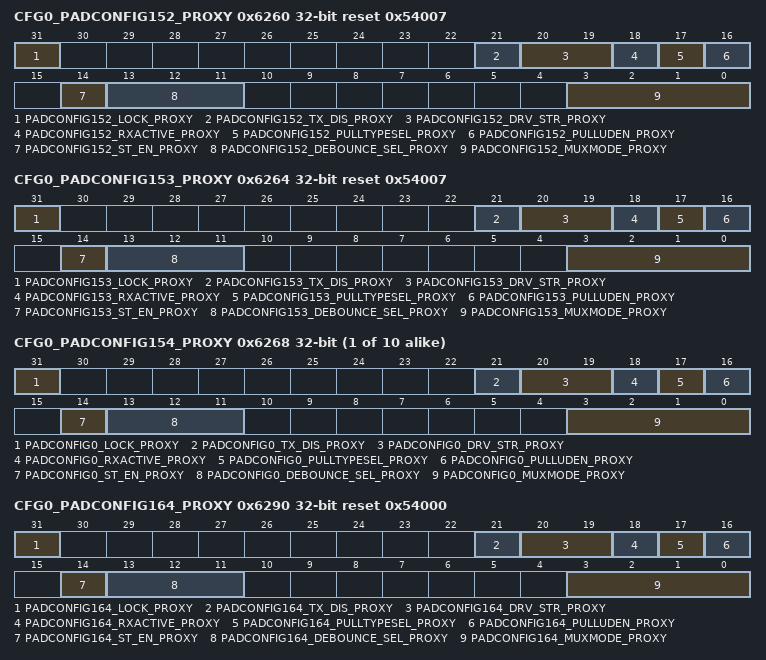
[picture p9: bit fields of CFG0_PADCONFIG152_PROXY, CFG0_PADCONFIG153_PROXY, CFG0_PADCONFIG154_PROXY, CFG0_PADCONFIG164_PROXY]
0x6260 CFG0_PADCONFIG152_PROXY reset 0x54007
  [31] PADCONFIG152_LOCK_PROXY — Lock 0 - Padconfig register is unlocked 1 - Padconfig register is locked from further writes
  [21] PADCONFIG152_TX_DIS_PROXY — Driver Disable 0 - Driver is enabled 1 - Driver is disabled
  [20:19] PADCONFIG152_DRV_STR_PROXY — Drive Strength Control . Selects the drive strength value for LVCMOS pins. (Does not apply to other pin types)
  [18] PADCONFIG152_RXACTIVE_PROXY — Input enable for the Pad 0 - Receiver disabled 1 - Receiver enabled
  [17] PADCONFIG152_PULLTYPESEL_PROXY — Pad Pullup / Pulldown type selection 0 - Pulldown selected 1 - Pullup selected
  [16] PADCONFIG152_PULLUDEN_PROXY — Pad Pullup / Pulldown enable. This is an active low signal. 0 - Pullup / Pulldown enabled 1 - Pullup / Pulldown disabled
  [14] PADCONFIG152_ST_EN_PROXY — Receiver Schmitt Trigger enable 0 - Schmitt trigger input disabled 1 - Schmitt trigger input enabled
  [13:11] PADCONFIG152_DEBOUNCE_SEL_PROXY — Selects the debouce period for the pad.
  [3:0] PADCONFIG152_MUXMODE_PROXY — Pad functional signal mux selection Field values (others are reserved): 4'b0000 - Mux Mode 0 4'b0001 - Mux Mode 1 4'b0010 - Mux Mode 2 4'b0011 - Mux Mode 3 4'b0100 - Mux Mode 4 4'b0101 - Mux Mode 5 4'b0110 - Mux Mode 6 4'b0111 - Mux Mode 7 4'b1000 - Mux Mode 8 4'b1001 - Mux Mode 9 4'b1010 - Mux Mode 10 4'b1011 - Mux Mode 11 4'b1100 - Mux Mode 12 4'b1101 - Mux Mode 13 4'b1110 - Mux Mode 14 4'b1111 - Mux Mode 15
0x6264 CFG0_PADCONFIG153_PROXY reset 0x54007
  [31] PADCONFIG153_LOCK_PROXY — Lock 0 - Padconfig register is unlocked 1 - Padconfig register is locked from further writes
  [21] PADCONFIG153_TX_DIS_PROXY — Driver Disable 0 - Driver is enabled 1 - Driver is disabled
  [20:19] PADCONFIG153_DRV_STR_PROXY — Drive Strength Control . Selects the drive strength value for LVCMOS pins. (Does not apply to other pin types)
  [18] PADCONFIG153_RXACTIVE_PROXY — Input enable for the Pad 0 - Receiver disabled 1 - Receiver enabled
  [17] PADCONFIG153_PULLTYPESEL_PROXY — Pad Pullup / Pulldown type selection 0 - Pulldown selected 1 - Pullup selected
  [16] PADCONFIG153_PULLUDEN_PROXY — Pad Pullup / Pulldown enable. This is an active low signal. 0 - Pullup / Pulldown enabled 1 - Pullup / Pulldown disabled
  [14] PADCONFIG153_ST_EN_PROXY — Receiver Schmitt Trigger enable 0 - Schmitt trigger input disabled 1 - Schmitt trigger input enabled
  [13:11] PADCONFIG153_DEBOUNCE_SEL_PROXY — Selects the debouce period for the pad.
  [3:0] PADCONFIG153_MUXMODE_PROXY — Pad functional signal mux selection Field values (others are reserved): 4'b0000 - Mux Mode 0 4'b0001 - Mux Mode 1 4'b0010 - Mux Mode 2 4'b0011 - Mux Mode 3 4'b0100 - Mux Mode 4 4'b0101 - Mux Mode 5 4'b0110 - Mux Mode 6 4'b0111 - Mux Mode 7 4'b1000 - Mux Mode 8 4'b1001 - Mux Mode 9 4'b1010 - Mux Mode 10 4'b1011 - Mux Mode 11 4'b1100 - Mux Mode 12 4'b1101 - Mux Mode 13 4'b1110 - Mux Mode 14 4'b1111 - Mux Mode 15
{0x6000+4i} CFG0_PADCONFIG{i}_PROXY (i=154..163)
  fields as CFG0_PADCONFIG0_PROXY
0x6290 CFG0_PADCONFIG164_PROXY reset 0x54000
  [31] PADCONFIG164_LOCK_PROXY — Lock 0 - Padconfig register is unlocked 1 - Padconfig register is locked from further writes
  [21] PADCONFIG164_TX_DIS_PROXY — Driver Disable 0 - Driver is enabled 1 - Driver is disabled
  [20:19] PADCONFIG164_DRV_STR_PROXY — Drive Strength Control . Selects the drive strength value for LVCMOS pins. (Does not apply to other pin types)
  [18] PADCONFIG164_RXACTIVE_PROXY — Input enable for the Pad 0 - Receiver disabled 1 - Receiver enabled
  [17] PADCONFIG164_PULLTYPESEL_PROXY — Pad Pullup / Pulldown type selection 0 - Pulldown selected 1 - Pullup selected
  [16] PADCONFIG164_PULLUDEN_PROXY — Pad Pullup / Pulldown enable. This is an active low signal. 0 - Pullup / Pulldown enabled 1 - Pullup / Pulldown disabled
  [14] PADCONFIG164_ST_EN_PROXY — Receiver Schmitt Trigger enable 0 - Schmitt trigger input disabled 1 - Schmitt trigger input enabled
  [13:11] PADCONFIG164_DEBOUNCE_SEL_PROXY — Selects the debouce period for the pad.
  [3:0] PADCONFIG164_MUXMODE_PROXY — Pad functional signal mux selection Field values (others are reserved): 4'b0000 - Mux Mode 0 4'b0001 - Mux Mode 1 4'b0010 - Mux Mode 2 4'b0011 - Mux Mode 3 4'b0100 - Mux Mode 4 4'b0101 - Mux Mode 5 4'b0110 - Mux Mode 6 4'b0111 - Mux Mode 7 4'b1000 - Mux Mode 8 4'b1001 - Mux Mode 9 4'b1010 - Mux Mode 10 4'b1011 - Mux Mode 11 4'b1100 - Mux Mode 12 4'b1101 - Mux Mode 13 4'b1110 - Mux Mode 14 4'b1111 - Mux Mode 15
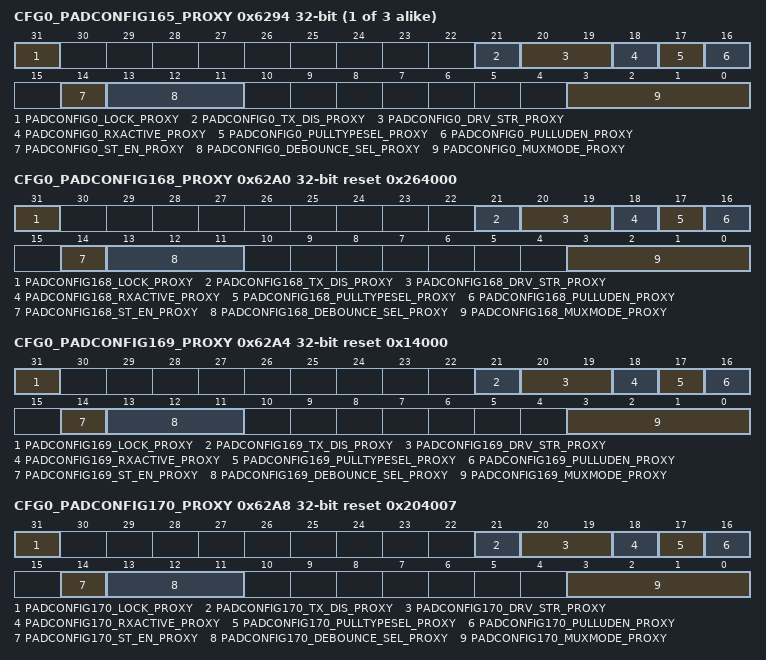
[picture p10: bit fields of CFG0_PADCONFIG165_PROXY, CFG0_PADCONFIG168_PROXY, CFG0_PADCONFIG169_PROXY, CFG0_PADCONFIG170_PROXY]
{0x6000+4i} CFG0_PADCONFIG{i}_PROXY (i=165..167)
  fields as CFG0_PADCONFIG0_PROXY
0x62A0 CFG0_PADCONFIG168_PROXY reset 0x264000
  [31] PADCONFIG168_LOCK_PROXY — Lock 0 - Padconfig register is unlocked 1 - Padconfig register is locked from further writes
  [21] PADCONFIG168_TX_DIS_PROXY — Driver Disable 0 - Driver is enabled 1 - Driver is disabled
  [20:19] PADCONFIG168_DRV_STR_PROXY — Drive Strength Control . Selects the drive strength value for LVCMOS pins. (Does not apply to other pin types)
  [18] PADCONFIG168_RXACTIVE_PROXY — Input enable for the Pad 0 - Receiver disabled 1 - Receiver enabled
  [17] PADCONFIG168_PULLTYPESEL_PROXY — Pad Pullup / Pulldown type selection 0 - Pulldown selected 1 - Pullup selected
  [16] PADCONFIG168_PULLUDEN_PROXY — Pad Pullup / Pulldown enable. This is an active low signal. 0 - Pullup / Pulldown enabled 1 - Pullup / Pulldown disabled
  [14] PADCONFIG168_ST_EN_PROXY — Receiver Schmitt Trigger enable 0 - Schmitt trigger input disabled 1 - Schmitt trigger input enabled
  [13:11] PADCONFIG168_DEBOUNCE_SEL_PROXY — Selects the debouce period for the pad.
  [3:0] PADCONFIG168_MUXMODE_PROXY — Pad functional signal mux selection Field values (others are reserved): 4'b0000 - Mux Mode 0 4'b0001 - Mux Mode 1 4'b0010 - Mux Mode 2 4'b0011 - Mux Mode 3 4'b0100 - Mux Mode 4 4'b0101 - Mux Mode 5 4'b0110 - Mux Mode 6 4'b0111 - Mux Mode 7 4'b1000 - Mux Mode 8 4'b1001 - Mux Mode 9 4'b1010 - Mux Mode 10 4'b1011 - Mux Mode 11 4'b1100 - Mux Mode 12 4'b1101 - Mux Mode 13 4'b1110 - Mux Mode 14 4'b1111 - Mux Mode 15
0x62A4 CFG0_PADCONFIG169_PROXY reset 0x14000
  [31] PADCONFIG169_LOCK_PROXY — Lock 0 - Padconfig register is unlocked 1 - Padconfig register is locked from further writes
  [21] PADCONFIG169_TX_DIS_PROXY — Driver Disable 0 - Driver is enabled 1 - Driver is disabled
  [20:19] PADCONFIG169_DRV_STR_PROXY — Drive Strength Control . Selects the drive strength value for LVCMOS pins. (Does not apply to other pin types)
  [18] PADCONFIG169_RXACTIVE_PROXY — Input enable for the Pad 0 - Receiver disabled 1 - Receiver enabled
  [17] PADCONFIG169_PULLTYPESEL_PROXY — Pad Pullup / Pulldown type selection 0 - Pulldown selected 1 - Pullup selected
  [16] PADCONFIG169_PULLUDEN_PROXY — Pad Pullup / Pulldown enable. This is an active low signal. 0 - Pullup / Pulldown enabled 1 - Pullup / Pulldown disabled
  [14] PADCONFIG169_ST_EN_PROXY — Receiver Schmitt Trigger enable 0 - Schmitt trigger input disabled 1 - Schmitt trigger input enabled
  [13:11] PADCONFIG169_DEBOUNCE_SEL_PROXY — Selects the debouce period for the pad.
  [3:0] PADCONFIG169_MUXMODE_PROXY — Pad functional signal mux selection Field values (others are reserved): 4'b0000 - Mux Mode 0 4'b0001 - Mux Mode 1 4'b0010 - Mux Mode 2 4'b0011 - Mux Mode 3 4'b0100 - Mux Mode 4 4'b0101 - Mux Mode 5 4'b0110 - Mux Mode 6 4'b0111 - Mux Mode 7 4'b1000 - Mux Mode 8 4'b1001 - Mux Mode 9 4'b1010 - Mux Mode 10 4'b1011 - Mux Mode 11 4'b1100 - Mux Mode 12 4'b1101 - Mux Mode 13 4'b1110 - Mux Mode 14 4'b1111 - Mux Mode 15
0x62A8 CFG0_PADCONFIG170_PROXY reset 0x204007
  [31] PADCONFIG170_LOCK_PROXY — Lock 0 - Padconfig register is unlocked 1 - Padconfig register is locked from further writes
  [21] PADCONFIG170_TX_DIS_PROXY — Driver Disable 0 - Driver is enabled 1 - Driver is disabled
  [20:19] PADCONFIG170_DRV_STR_PROXY — Drive Strength Control . Selects the drive strength value for LVCMOS pins. (Does not apply to other pin types)
  [18] PADCONFIG170_RXACTIVE_PROXY — Input enable for the Pad 0 - Receiver disabled 1 - Receiver enabled
  [17] PADCONFIG170_PULLTYPESEL_PROXY — Pad Pullup / Pulldown type selection 0 - Pulldown selected 1 - Pullup selected
  [16] PADCONFIG170_PULLUDEN_PROXY — Pad Pullup / Pulldown enable. This is an active low signal. 0 - Pullup / Pulldown enabled 1 - Pullup / Pulldown disabled
  [14] PADCONFIG170_ST_EN_PROXY — Receiver Schmitt Trigger enable 0 - Schmitt trigger input disabled 1 - Schmitt trigger input enabled
  [13:11] PADCONFIG170_DEBOUNCE_SEL_PROXY — Selects the debouce period for the pad.
  [3:0] PADCONFIG170_MUXMODE_PROXY — Pad functional signal mux selection Field values (others are reserved): 4'b0000 - Mux Mode 0 4'b0001 - Mux Mode 1 4'b0010 - Mux Mode 2 4'b0011 - Mux Mode 3 4'b0100 - Mux Mode 4 4'b0101 - Mux Mode 5 4'b0110 - Mux Mode 6 4'b0111 - Mux Mode 7 4'b1000 - Mux Mode 8 4'b1001 - Mux Mode 9 4'b1010 - Mux Mode 10 4'b1011 - Mux Mode 11 4'b1100 - Mux Mode 12 4'b1101 - Mux Mode 13 4'b1110 - Mux Mode 14 4'b1111 - Mux Mode 15
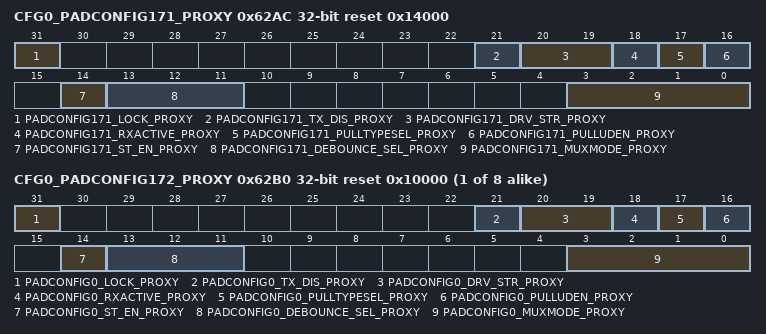
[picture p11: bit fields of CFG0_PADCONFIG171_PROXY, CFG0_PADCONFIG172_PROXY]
0x62AC CFG0_PADCONFIG171_PROXY reset 0x14000
  [31] PADCONFIG171_LOCK_PROXY — Lock 0 - Padconfig register is unlocked 1 - Padconfig register is locked from further writes
  [21] PADCONFIG171_TX_DIS_PROXY — Driver Disable 0 - Driver is enabled 1 - Driver is disabled
  [20:19] PADCONFIG171_DRV_STR_PROXY — Drive Strength Control . Selects the drive strength value for LVCMOS pins. (Does not apply to other pin types)
  [18] PADCONFIG171_RXACTIVE_PROXY — Input enable for the Pad 0 - Receiver disabled 1 - Receiver enabled
  [17] PADCONFIG171_PULLTYPESEL_PROXY — Pad Pullup / Pulldown type selection 0 - Pulldown selected 1 - Pullup selected
  [16] PADCONFIG171_PULLUDEN_PROXY — Pad Pullup / Pulldown enable. This is an active low signal. 0 - Pullup / Pulldown enabled 1 - Pullup / Pulldown disabled
  [14] PADCONFIG171_ST_EN_PROXY — Receiver Schmitt Trigger enable 0 - Schmitt trigger input disabled 1 - Schmitt trigger input enabled
  [13:11] PADCONFIG171_DEBOUNCE_SEL_PROXY — Selects the debouce period for the pad.
  [3:0] PADCONFIG171_MUXMODE_PROXY — Pad functional signal mux selection Field values (others are reserved): 4'b0000 - Mux Mode 0 4'b0001 - Mux Mode 1 4'b0010 - Mux Mode 2 4'b0011 - Mux Mode 3 4'b0100 - Mux Mode 4 4'b0101 - Mux Mode 5 4'b0110 - Mux Mode 6 4'b0111 - Mux Mode 7 4'b1000 - Mux Mode 8 4'b1001 - Mux Mode 9 4'b1010 - Mux Mode 10 4'b1011 - Mux Mode 11 4'b1100 - Mux Mode 12 4'b1101 - Mux Mode 13 4'b1110 - Mux Mode 14 4'b1111 - Mux Mode 15
{0x6000+4i} CFG0_PADCONFIG{i}_PROXY reset 0x10000 (i=172..179)
  fields as CFG0_PADCONFIG0_PROXY
0x7008 CFG0_LOCK1_KICK0_PROXY reset 0x0
  [31:0] LOCK1_KICK0_PROXY — - KICK0 component
0x700C CFG0_LOCK1_KICK1_PROXY reset 0x0
  [31:0] LOCK1_KICK1_PROXY — - KICK1 component
